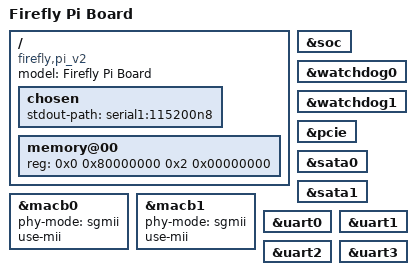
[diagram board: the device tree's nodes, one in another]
/dts-v1/;
/memreserve/ 0x80000000 0x10000;

#include "firefly_pi_v2.dtsi"
#include "dt-bindings/gpio/gpio.h"

/{
	model = "Firefly Pi Board";
	compatible = "firefly,pi_v2";

	chosen {
		stdout-path = "serial1:115200n8";
	};

	memory@00{
		device_type = "memory";
		reg = <0x0 0x80000000 0x2 0x00000000>;
	};
};

&soc {

};

&watchdog0 {
	status = "okay";
};

&watchdog1 {
	status = "okay";
};

&pcie {
	status = "okay";
};

/*&usb3_0 {
	status = "okay";
};*/

&sata0 {
	status = "okay";
};

&sata1 {
	status = "okay";
};

&macb0 {
	phy-mode = "sgmii";
	use-mii;
	status = "okay";
};

&macb1 {
	phy-mode = "sgmii";
	use-mii;
	status = "okay";
};

&uart0 {
	status = "okay";
};

&uart1 {
	status = "okay";
};

&uart2 {
	status = "okay";
};

&uart3 {
	status = "okay";
};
